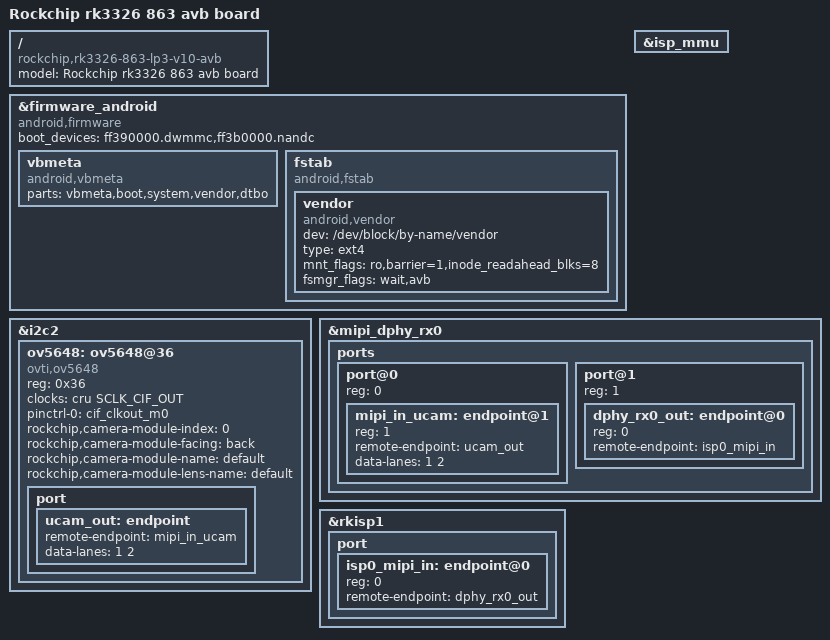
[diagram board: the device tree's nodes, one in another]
// SPDX-License-Identifier: (GPL-2.0+ OR MIT)
/*
 * Copyright (c) 2017 Fuzhou Rockchip Electronics Co., Ltd
 */

/dts-v1/;
#include "rk3326-h710.dtsi"

/ {
	model = "Rockchip rk3326 863 avb board";
	compatible = "rockchip,rk3326-863-lp3-v10-avb", "rockchip,rk3326";
};

&firmware_android {
	compatible = "android,firmware";
	boot_devices = "ff390000.dwmmc,ff3b0000.nandc";
	vbmeta {
		compatible = "android,vbmeta";
		parts = "vbmeta,boot,system,vendor,dtbo";
	};
	fstab {
		compatible = "android,fstab";
		vendor {
			compatible = "android,vendor";
			dev = "/dev/block/by-name/vendor";
			type = "ext4";
			mnt_flags = "ro,barrier=1,inode_readahead_blks=8";
			fsmgr_flags = "wait,avb";
		};
	};
};

&i2c2 {
	status = "okay";

	ov5648: ov5648@36 {
                status = "okay";
                compatible = "ovti,ov5648";
                reg = <0x36>;
                clocks = <&cru SCLK_CIF_OUT>;
                clock-names = "xvclk";

//                avdd-supply = <&vcc2v8_dvp>;
//                dovdd-supply = <&vcc1v8_dvp>;
//                dvdd-supply = <&vdd1v5_dvp>;

		pinctrl-names = "rockchip,camera_default";
                pinctrl-0 = <&cif_clkout_m0>;

                rockchip,camera-module-index = <0>;
                rockchip,camera-module-facing = "back";
                rockchip,camera-module-name = "default";
                rockchip,camera-module-lens-name = "default";

		//pwdn-gpios = <&gpio2 RK_PB5 GPIO_ACTIVE_LOW>;
                //reset-gpios = <&gpio2 RK_PB6 GPIO_ACTIVE_LOW>;
                port {
                        ucam_out: endpoint {
                                remote-endpoint = <&mipi_in_ucam>;
                                data-lanes = <1 2>;
                        };
                };
        };
};

&isp_mmu {
	status = "okay";
};

&mipi_dphy_rx0 {
	status = "okay";

	ports {
		#address-cells = <1>;
		#size-cells = <0>;

		port@0 {
			reg = <0>;
			#address-cells = <1>;
			#size-cells = <0>;

			mipi_in_ucam: endpoint@1 {
				reg = <1>;
				remote-endpoint = <&ucam_out>;
				data-lanes = <1 2>;
			};
		};

		port@1 {
			reg = <1>;
			#address-cells = <1>;
			#size-cells = <0>;

			dphy_rx0_out: endpoint@0 {
				reg = <0>;
				remote-endpoint = <&isp0_mipi_in>;
			};
		};
	};
};

&rkisp1 {
	status = "okay";

	port {
		#address-cells = <1>;
		#size-cells = <0>;

		isp0_mipi_in: endpoint@0 {
			reg = <0>;
			remote-endpoint = <&dphy_rx0_out>;
		};
	};
};

